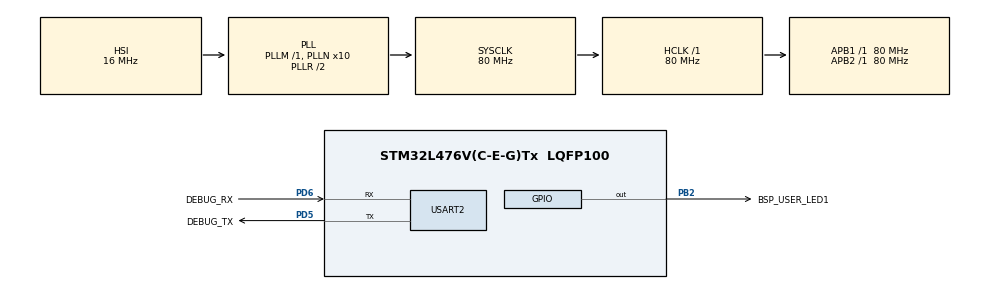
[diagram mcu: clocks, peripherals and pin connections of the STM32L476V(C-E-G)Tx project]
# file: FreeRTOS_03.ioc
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FREERTOS.BinarySemaphores01=MyToken,Dynamic,NULL
FREERTOS.Tasks01=Boss,24,256,BossFunction,Default,NULL,Dynamic,NULL,NULL;Employee,16,256,EmployeeFunction,Default,NULL,Dynamic,NULL,NULL;Start,40,256,MainThread,Default,NULL,Dynamic,NULL,NULL
FREERTOS.configTOTAL_HEAP_SIZE=8000
Mcu.Family=STM32L4
Mcu.Name=STM32L476V(C-E-G)Tx
Mcu.Package=LQFP100
NVIC.PriorityGroup=NVIC_PRIORITYGROUP_4
NVIC.TIM6_DAC_IRQn=true\:0\:0\:false\:false\:true\:false\:false\:true
NVIC.TimeBase=TIM6_DAC_IRQn
NVIC.TimeBaseIP=TIM6
PA13\ (JTMS-SWDIO).Mode=Serial_Wire
PA13\ (JTMS-SWDIO).Signal=SYS_JTMS-SWDIO
PA14\ (JTCK-SWCLK).Mode=Serial_Wire
PA14\ (JTCK-SWCLK).Signal=SYS_JTCK-SWCLK
PB2.GPIO_Label=BSP_USER_LED1
PB2.GPIO_Speed=GPIO_SPEED_FREQ_HIGH
PB2.Signal=GPIO_Output
PD5.GPIO_Label=DEBUG_TX
PD5.Mode=Asynchronous
PD5.Signal=USART2_TX
PD6.GPIO_Label=DEBUG_RX
PD6.Mode=Asynchronous
PD6.Signal=USART2_RX
ProjectManager.HeapSize=0x200
ProjectManager.StackSize=0x400
ProjectManager.TargetToolchain=STM32CubeIDE
RCC.ADCFreq_Value=64000000
RCC.AHBFreq_Value=80000000
RCC.APB1Freq_Value=80000000
RCC.APB1TimFreq_Value=80000000
RCC.APB2Freq_Value=80000000
RCC.APB2TimFreq_Value=80000000
RCC.CortexFreq_Value=80000000
RCC.HCLKFreq_Value=80000000
RCC.HSE_VALUE=8000000
RCC.HSI_VALUE=16000000
RCC.LSE_VALUE=32768
RCC.MSI_VALUE=4000000
RCC.PLLN=10
RCC.PLLSourceVirtual=RCC_PLLSOURCE_HSI
RCC.SYSCLKFreq_VALUE=80000000
RCC.SYSCLKSource=RCC_SYSCLKSOURCE_PLLCLK
RCC.USBFreq_Value=64000000
RCC.VCOOutputFreq_Value=160000000
USART2.VirtualMode-Asynchronous=VM_ASYNC
VP_FREERTOS_VS_CMSIS_V2.Mode=CMSIS_V2
VP_SYS_VS_tim6.Mode=TIM6
board=custom

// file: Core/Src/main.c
/* USER CODE BEGIN Header */
/**
 ******************************************************************************
 * @file           : main.c
 * @brief          : Main program body
 ******************************************************************************
 * @attention
 *
 * <h2><center>&copy; Copyright (c) 2021 STMicroelectronics.
 * All rights reserved.</center></h2>
 *
 * This software component is licensed by ST under BSD 3-Clause license,
 * the "License"; You may not use this file except in compliance with the
 * License. You may obtain a copy of the License at:
 *                        opensource.org/licenses/BSD-3-Clause
 *
 ******************************************************************************
 */
/* ******************************************************************************
 DO WHAT THE FUCK YOU WANT TO PUBLIC LICENSE
 Version 2, December 2021

 Copyright (C) 2021 Mahendra Sondagar <mahendrasondagar08@gmail.com>
 Everyone is permitted to copy and distribute verbatim or modified
 copies of this license document, and changing it is allowed as long
 as the name is changed.

 DO WHAT THE FUCK YOU WANT TO PUBLIC LICENSE
 TERMS AND CONDITIONS FOR COPYING, DISTRIBUTION AND MODIFICATION
 0. You just DO WHAT THE FUCK YOU WANT TO.

 Coded: Sun, 12th Sep, 2021 / 16:56 PM
 ****************************************************/
/* USER CODE END Header */
#include "main.h"
#include "cmsis_os.h"

/* USER CODE BEGIN PM */
#define WELCOME_MSG     "--------------------------------------------------\r\n"\
                        "                 Hello World!                     \r\n"\
	                    "    This is the FreeRTOS Binary Semaphore Example \r\n"\
						"          Coded By: Mahendra Sondagar             \r\n"\
						"        <mahendrasondagar08@gmail.com>            \r\n"\
						"--------------------------------------------------\r\n"
/* USER CODE END PM */

UART_HandleTypeDef huart2;

/* Definitions for Boss */
osThreadId_t BossHandle;
const osThreadAttr_t Boss_attributes = { .name = "Boss", .priority =
		(osPriority_t) osPriorityNormal, .stack_size = 256 * 4 };
/* Definitions for Employee */
osThreadId_t EmployeeHandle;
const osThreadAttr_t Employee_attributes = { .name = "Employee", .priority =
		(osPriority_t) osPriorityBelowNormal, .stack_size = 256 * 4 };
/* Definitions for Start */
osThreadId_t StartHandle;
const osThreadAttr_t Start_attributes = { .name = "Start", .priority =
		(osPriority_t) osPriorityHigh, .stack_size = 256 * 4 };
/* Definitions for MyToken */
osSemaphoreId_t MyTokenHandle;
const osSemaphoreAttr_t MyToken_attributes = { .name = "MyToken" };

void SystemClock_Config(void);
static void MX_GPIO_Init(void);
static void MX_USART2_UART_Init(void);
void BossFunction(void *argument);
void EmployeeFunction(void *argument);
void MainThread(void *argument);

int main(void) {

	/* MCU Configuration--------------------------------------------------------*/

	/* Reset of all peripherals, Initializes the Flash interface and the Systick. */
	HAL_Init();

	/* Configure the system clock */
	SystemClock_Config();

	/* Initialize all configured peripherals */
	MX_GPIO_Init();
	MX_USART2_UART_Init();
	/* USER CODE BEGIN 2 */
	HAL_Delay(250);
	KERNEL_DBG(WELCOME_MSG);

	/* USER CODE END 2 */

	/* Init scheduler */
	osKernelInitialize();

	/* Create the semaphores(s) */
	/* creation of MyToken */
	MyTokenHandle = osSemaphoreNew(1, 1, &MyToken_attributes);

	/* Create the thread(s) */

	/* creation of Start */
	StartHandle = osThreadNew(MainThread, NULL, &Start_attributes);
	if (StartHandle == NULL) {
		KERNEL_DBG("Failed to create MainThread");
	}

	/* Start scheduler */
	osKernelStart();

	/* We should never get here as control is now taken by the scheduler */
	/* Infinite loop */
	while (1) {

	}
}

void SystemClock_Config(void) {
	RCC_OscInitTypeDef RCC_OscInitStruct = { 0 };
	RCC_ClkInitTypeDef RCC_ClkInitStruct = { 0 };
	RCC_PeriphCLKInitTypeDef PeriphClkInit = { 0 };

	/** Initializes the RCC Oscillators according to the specified parameters
	 * in the RCC_OscInitTypeDef structure.
	 */
	RCC_OscInitStruct.OscillatorType = RCC_OSCILLATORTYPE_HSI;
	RCC_OscInitStruct.HSIState = RCC_HSI_ON;
	RCC_OscInitStruct.HSICalibrationValue = RCC_HSICALIBRATION_DEFAULT;
	RCC_OscInitStruct.PLL.PLLState = RCC_PLL_ON;
	RCC_OscInitStruct.PLL.PLLSource = RCC_PLLSOURCE_HSI;
	RCC_OscInitStruct.PLL.PLLM = 1;
	RCC_OscInitStruct.PLL.PLLN = 10;
	RCC_OscInitStruct.PLL.PLLP = RCC_PLLP_DIV7;
	RCC_OscInitStruct.PLL.PLLQ = RCC_PLLQ_DIV2;
	RCC_OscInitStruct.PLL.PLLR = RCC_PLLR_DIV2;
	if (HAL_RCC_OscConfig(&RCC_OscInitStruct) != HAL_OK) {
		Error_Handler();
	}
	/** Initializes the CPU, AHB and APB buses clocks
	 */
	RCC_ClkInitStruct.ClockType = RCC_CLOCKTYPE_HCLK | RCC_CLOCKTYPE_SYSCLK
			| RCC_CLOCKTYPE_PCLK1 | RCC_CLOCKTYPE_PCLK2;
	RCC_ClkInitStruct.SYSCLKSource = RCC_SYSCLKSOURCE_PLLCLK;
	RCC_ClkInitStruct.AHBCLKDivider = RCC_SYSCLK_DIV1;
	RCC_ClkInitStruct.APB1CLKDivider = RCC_HCLK_DIV1;
	RCC_ClkInitStruct.APB2CLKDivider = RCC_HCLK_DIV1;

	if (HAL_RCC_ClockConfig(&RCC_ClkInitStruct, FLASH_LATENCY_4) != HAL_OK) {
		Error_Handler();
	}
	PeriphClkInit.PeriphClockSelection = RCC_PERIPHCLK_USART2;
	PeriphClkInit.Usart2ClockSelection = RCC_USART2CLKSOURCE_PCLK1;
	if (HAL_RCCEx_PeriphCLKConfig(&PeriphClkInit) != HAL_OK) {
		Error_Handler();
	}
	/** Configure the main internal regulator output voltage
	 */
	if (HAL_PWREx_ControlVoltageScaling(PWR_REGULATOR_VOLTAGE_SCALE1)
			!= HAL_OK) {
		Error_Handler();
	}
}

static void MX_USART2_UART_Init(void) {

	huart2.Instance = USART2;
	huart2.Init.BaudRate = 115200;
	huart2.Init.WordLength = UART_WORDLENGTH_8B;
	huart2.Init.StopBits = UART_STOPBITS_1;
	huart2.Init.Parity = UART_PARITY_NONE;
	huart2.Init.Mode = UART_MODE_TX_RX;
	huart2.Init.HwFlowCtl = UART_HWCONTROL_NONE;
	huart2.Init.OverSampling = UART_OVERSAMPLING_16;
	huart2.Init.OneBitSampling = UART_ONE_BIT_SAMPLE_DISABLE;
	huart2.AdvancedInit.AdvFeatureInit = UART_ADVFEATURE_NO_INIT;
	if (HAL_UART_Init(&huart2) != HAL_OK) {
		Error_Handler();
	}

}

static void MX_GPIO_Init(void) {
	GPIO_InitTypeDef GPIO_InitStruct = { 0 };

	/* GPIO Ports Clock Enable */
	__HAL_RCC_GPIOB_CLK_ENABLE();
	__HAL_RCC_GPIOA_CLK_ENABLE();
	__HAL_RCC_GPIOD_CLK_ENABLE();

	/*Configure GPIO pin Output Level */
	HAL_GPIO_WritePin(BSP_USER_LED1_GPIO_Port, BSP_USER_LED1_Pin,
			GPIO_PIN_RESET);

	/*Configure GPIO pin : BSP_USER_LED1_Pin */
	GPIO_InitStruct.Pin = BSP_USER_LED1_Pin;
	GPIO_InitStruct.Mode = GPIO_MODE_OUTPUT_PP;
	GPIO_InitStruct.Pull = GPIO_NOPULL;
	GPIO_InitStruct.Speed = GPIO_SPEED_FREQ_HIGH;
	HAL_GPIO_Init(BSP_USER_LED1_GPIO_Port, &GPIO_InitStruct);

}

void BossFunction(void *argument) {
	/* USER CODE BEGIN 5 */
	/* Infinite loop */
	for (;;) {
		/* Sending the Binary semaphore at every 2 sec */
		osSemaphoreRelease(MyTokenHandle);
		osDelay(2000);
	}
	/* USER CODE END 5 */
}

void EmployeeFunction(void *argument) {
	/* USER CODE BEGIN EmployeeFunction */
	/* Infinite loop */
	for (;;) {
		/*Waiting forever for semaphore */
		if (osSemaphoreAcquire(MyTokenHandle, osWaitForever) == osOK) {
			KERNEL_DBG("Employee allocated task from BOSS!");
			HAL_GPIO_TogglePin(BSP_USER_LED1_GPIO_Port, BSP_USER_LED1_Pin);
		}
	}
	/* USER CODE END EmployeeFunction */
}

void MainThread(void *argument) {
	/* USER CODE BEGIN MainThread */
	/* Create the thread(s) */
	/* creation of Boss */
	BossHandle = osThreadNew(BossFunction, NULL, &Boss_attributes);
	if (BossHandle == NULL) {
		KERNEL_DBG("Failed to create BossThread");
	}

	/* creation of Employee */
	EmployeeHandle = osThreadNew(EmployeeFunction, NULL, &Employee_attributes);
	if (EmployeeHandle == NULL) {
		KERNEL_DBG("Failed to create Employee Thread");
	}
	/* Infinite loop */
	for (;;) {
		osThreadTerminate(StartHandle);
	}
	/* USER CODE END MainThread */
}

void HAL_TIM_PeriodElapsedCallback(TIM_HandleTypeDef *htim) {
	if (htim->Instance == TIM6) {
		HAL_IncTick();
	}
}

void Error_Handler(void) {
	__disable_irq();
	while (1) {
	}
}

/************************ (C) COPYRIGHT STMicroelectronics *****END OF FILE****/
